# tcp3d_dma register map
Vendor: Texas Instruments
Peripheral module from a debugger description file (folder tcp3d).
Registers are 32-bit, read-write, no defined reset value unless marked. A register's access mark holds for its fields unless they carry their own. Offsets are as the file gives them; lines under a group give offsets from that group; [hi:lo] are bit positions; {n}, {i} and the like mark numbered series; 'fields as' and 'values as' point back to an identical list; <NAME> marks a mode.

## TCP3D_3_DMA
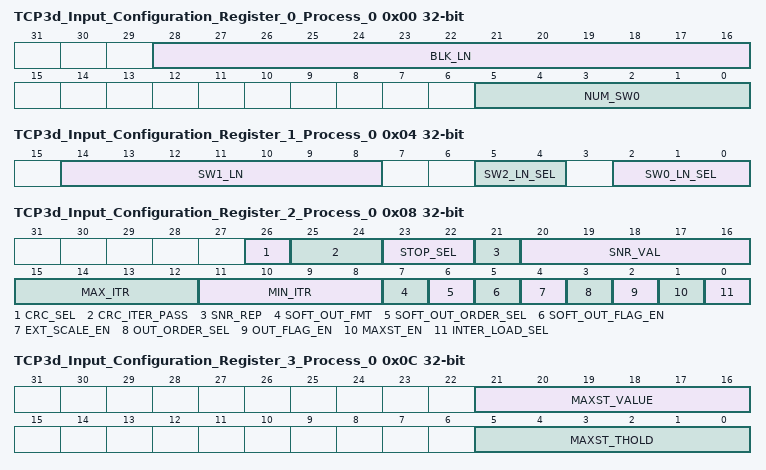
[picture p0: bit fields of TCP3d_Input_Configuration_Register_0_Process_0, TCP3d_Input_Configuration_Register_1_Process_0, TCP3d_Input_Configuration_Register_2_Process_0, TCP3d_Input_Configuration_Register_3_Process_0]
0x00 TCP3d_Input_Configuration_Register_0_Process_0
  [28:16] BLK_LN — Block size minus 1 i.e. 40
  [5:0] NUM_SW0 — Number of SW0s per subblock, 0 = off Value of 63 is illegal
0x04 TCP3d_Input_Configuration_Register_1_Process_0
  [14:8] SW1_LN — SW1 length
  [5:4] SW2_LN_SEL — SW2 length
  [2:0] SW0_LN_SEL — Select length of SW0
0x08 TCP3d_Input_Configuration_Register_2_Process_0
  [26] CRC_SEL — LTE CRC polynomial select
  [25:24] CRC_ITER_PASS — Select number of consecutive LTE CRC matches as stopping criterion
  [23:22] STOP_SEL — Stopping criteria select
  [21] SNR_REP — SNR Reporting Enable. Always enabled if STOP_SEL = 10 or 11 regardless of this bit
  [20:16] SNR_VAL — SNR threshold, in dB, used as a stopping criterion. The turbo decoding will stop as soon as the decoded signal SNR > SNR threshold
  [15:12] MAX_ITR — Maximum number of iterations
  [11:8] MIN_ITR — Minimum number of iterations
  [7] SOFT_OUT_FMT — Systematic, parity 1 and parity 0 soft output bit formats
  [6] SOFT_OUT_ORDER_SEL — Format of soft output data in big endian mode. This bit has no effect if in little endian mode
  [5] SOFT_OUT_FLAG_EN — Soft output bits read flag
  [4] EXT_SCALE_EN — Extrinsic scale enable
  [3] OUT_ORDER_SEL — Bit ordering of hard decisions
  [2] OUT_FLAG_EN — Output status registers read flag
  [1] MAXST_EN — Max Star enable
  [0] INTER_LOAD_SEL — Interleaver table load select
0x0C TCP3d_Input_Configuration_Register_3_Process_0
  [21:16] MAXST_VALUE — Max Star value
  [5:0] MAXST_THOLD — Max Star threshold
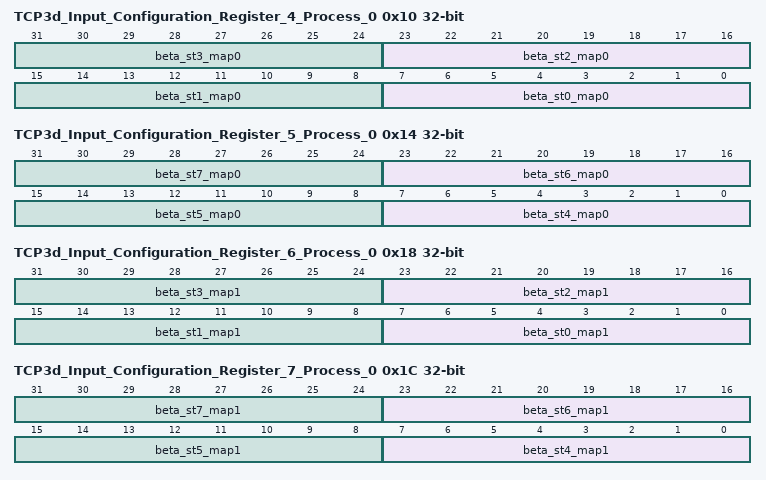
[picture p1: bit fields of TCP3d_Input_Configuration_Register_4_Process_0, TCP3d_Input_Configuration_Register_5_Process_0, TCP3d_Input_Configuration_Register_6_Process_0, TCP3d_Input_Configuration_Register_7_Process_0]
0x10 TCP3d_Input_Configuration_Register_4_Process_0
  [8n+7:8n] beta_st{n}_map0 (n=0..3) — Beta state {n} for MAP0
0x14 TCP3d_Input_Configuration_Register_5_Process_0
  [8n-25:8n-32] beta_st{n}_map0 (n=4..7) — Beta state {n} for MAP0
0x18 TCP3d_Input_Configuration_Register_6_Process_0
  [8n+7:8n] beta_st{n}_map1 (n=0..3) — Beta state {n} for MAP1
0x1C TCP3d_Input_Configuration_Register_7_Process_0
  [8n-25:8n-32] beta_st{n}_map1 (n=4..7) — Beta state {n} for MAP1
{0x0+4i} TCP3d_Input_Configuration_Register_{i}_Process_0 (i=8..11)
  [23:0] EXT_SCALE_{4i-32}_{4i-29} — Extrinsic scale factor {4i-32} through {4i-29}
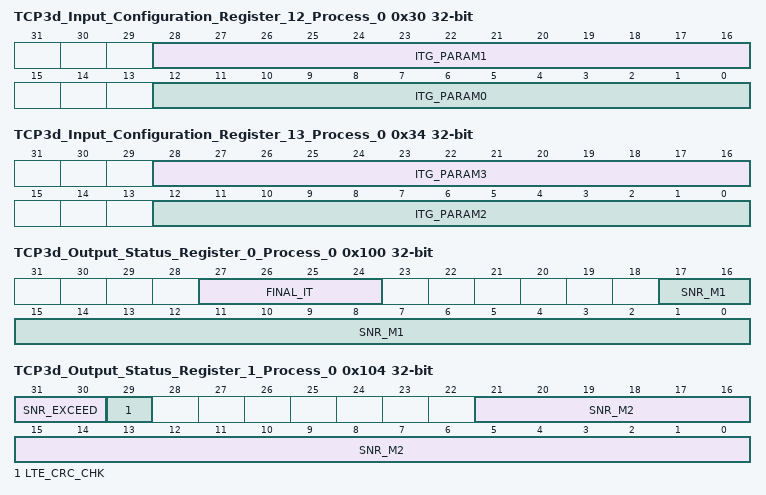
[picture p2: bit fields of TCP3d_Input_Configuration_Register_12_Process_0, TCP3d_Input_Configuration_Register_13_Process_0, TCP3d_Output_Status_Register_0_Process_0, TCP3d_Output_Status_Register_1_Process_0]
0x30 TCP3d_Input_Configuration_Register_12_Process_0
  [28:16] ITG_PARAM1, [12:0] ITG_PARAM0
0x34 TCP3d_Input_Configuration_Register_13_Process_0
  [28:16] ITG_PARAM3, [12:0] ITG_PARAM2
0x38 TCP3d_Input_Configuration_Register_14_Process_0
  [12:0] ITG_PARAM4
0x3C TCP3d_Trigger_Control_Register_Process_0 wo
  [0] TRIG — Trigger to start new decode
0x100 TCP3d_Output_Status_Register_0_Process_0 ro
  [27:24] FINAL_IT — Number of decoded iterations
  [17:0] SNR_M1 — First moment of SNR calculations
0x104 TCP3d_Output_Status_Register_1_Process_0 ro
  [31:30] SNR_EXCEED — SNR status. Final status held
  [29] LTE_CRC_CHK — LTE CRC Check Status
  [21:0] SNR_M2 — Second moment of SNR calculations
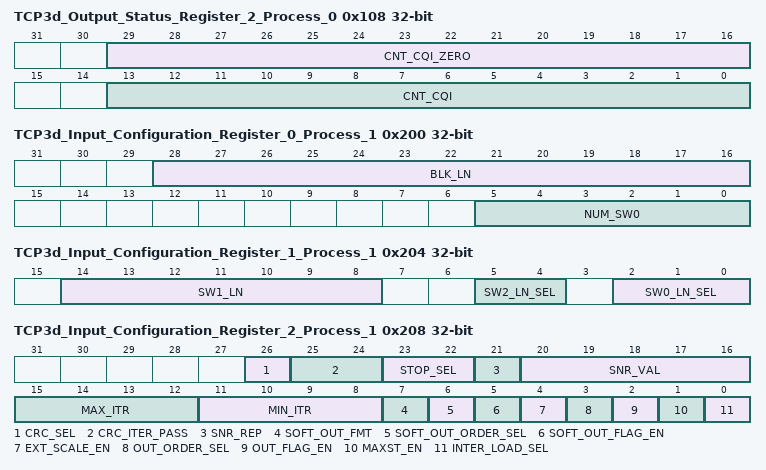
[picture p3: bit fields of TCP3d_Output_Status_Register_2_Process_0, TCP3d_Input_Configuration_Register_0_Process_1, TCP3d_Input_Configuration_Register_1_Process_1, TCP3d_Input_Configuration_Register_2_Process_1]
0x108 TCP3d_Output_Status_Register_2_Process_0 ro
  [29:16] CNT_CQI_ZERO — CQI logic reports the number of systematics that have a value of zero 000000, which is ambiguous i.e. does not imply a soft bit of either 0 or 1, here
  [13:0] CNT_CQI — Channel Quality Indicator measurement. Reports the number of mismatches between systematics and hard decisions
0x200 TCP3d_Input_Configuration_Register_0_Process_1
  fields as TCP3d_Input_Configuration_Register_0_Process_0
0x204 TCP3d_Input_Configuration_Register_1_Process_1
  fields as TCP3d_Input_Configuration_Register_1_Process_0
0x208 TCP3d_Input_Configuration_Register_2_Process_1
  fields as TCP3d_Input_Configuration_Register_2_Process_0
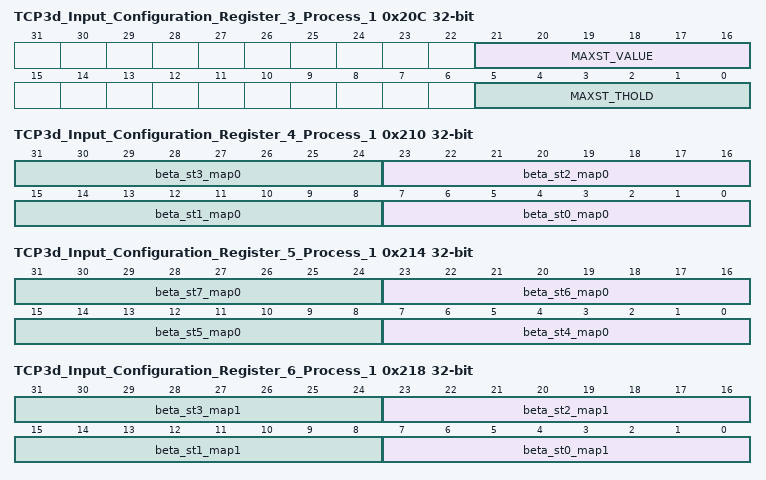
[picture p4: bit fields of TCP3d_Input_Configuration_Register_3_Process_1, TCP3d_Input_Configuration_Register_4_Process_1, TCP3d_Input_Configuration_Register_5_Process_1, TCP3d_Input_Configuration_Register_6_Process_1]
0x20C TCP3d_Input_Configuration_Register_3_Process_1
  fields as TCP3d_Input_Configuration_Register_3_Process_0
0x210 TCP3d_Input_Configuration_Register_4_Process_1
  [8n+7:8n] beta_st{n}_map0 (n=0..3) — Beta state {n} for MAP0
0x214 TCP3d_Input_Configuration_Register_5_Process_1
  [8n-25:8n-32] beta_st{n}_map0 (n=4..7) — Beta state {n} for MAP0
0x218 TCP3d_Input_Configuration_Register_6_Process_1
  [8n+7:8n] beta_st{n}_map1 (n=0..3) — Beta state {n} for MAP1
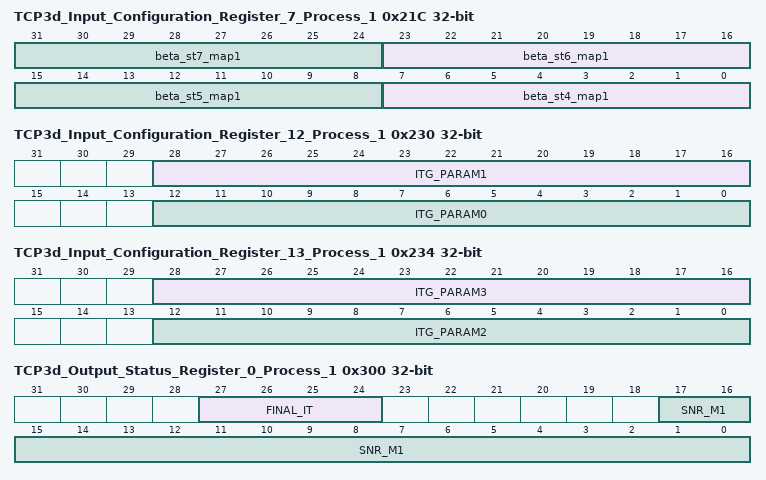
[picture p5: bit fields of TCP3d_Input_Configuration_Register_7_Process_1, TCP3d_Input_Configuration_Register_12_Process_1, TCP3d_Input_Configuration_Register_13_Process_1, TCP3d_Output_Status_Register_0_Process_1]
0x21C TCP3d_Input_Configuration_Register_7_Process_1
  [8n-25:8n-32] beta_st{n}_map1 (n=4..7) — Beta state {n} for MAP1
{0x200+4i} TCP3d_Input_Configuration_Register_{i}_Process_1 (i=8..11)
  fields as TCP3d_Input_Configuration_Register_8_Process_0
0x230 TCP3d_Input_Configuration_Register_12_Process_1
  [28:16] ITG_PARAM1, [12:0] ITG_PARAM0
0x234 TCP3d_Input_Configuration_Register_13_Process_1
  [28:16] ITG_PARAM3, [12:0] ITG_PARAM2
0x238 TCP3d_Input_Configuration_Register_14_Process_1
  [12:0] ITG_PARAM4
0x23C TCP3d_Trigger_Control_Register_Process_1 wo
  [0] TRIG — Trigger to start new decode
0x300 TCP3d_Output_Status_Register_0_Process_1 ro
  fields as TCP3d_Output_Status_Register_0_Process_0
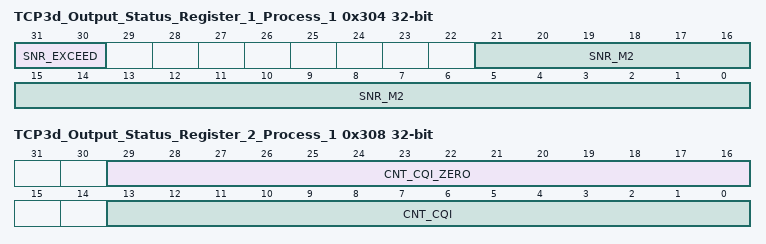
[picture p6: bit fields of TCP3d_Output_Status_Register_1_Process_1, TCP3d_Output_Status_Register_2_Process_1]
0x304 TCP3d_Output_Status_Register_1_Process_1 ro
  [31:30] SNR_EXCEED — SNR status. Final status held
  [21:0] SNR_M2 — Second moment of SNR calculations
0x308 TCP3d_Output_Status_Register_2_Process_1 ro
  fields as TCP3d_Output_Status_Register_2_Process_0
